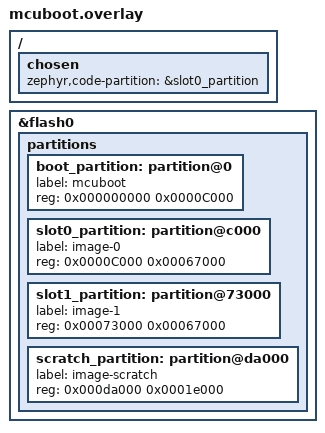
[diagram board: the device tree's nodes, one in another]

/ {
	chosen {
		zephyr,code-partition = &slot0_partition;
	};
};

&flash0 {
	partitions {
		boot_partition: partition@0 {
			label = "mcuboot";
			reg = <0x000000000 0x0000C000>;
		};
		slot0_partition: partition@c000 {
			label = "image-0";
			reg = <0x0000C000 0x00067000>;
		};
		slot1_partition: partition@73000 {
			label = "image-1";
			reg = <0x00073000 0x00067000>;
		};
		scratch_partition: partition@da000 {
			label = "image-scratch";
			reg = <0x000da000 0x0001e000>;
		};
	};
};
